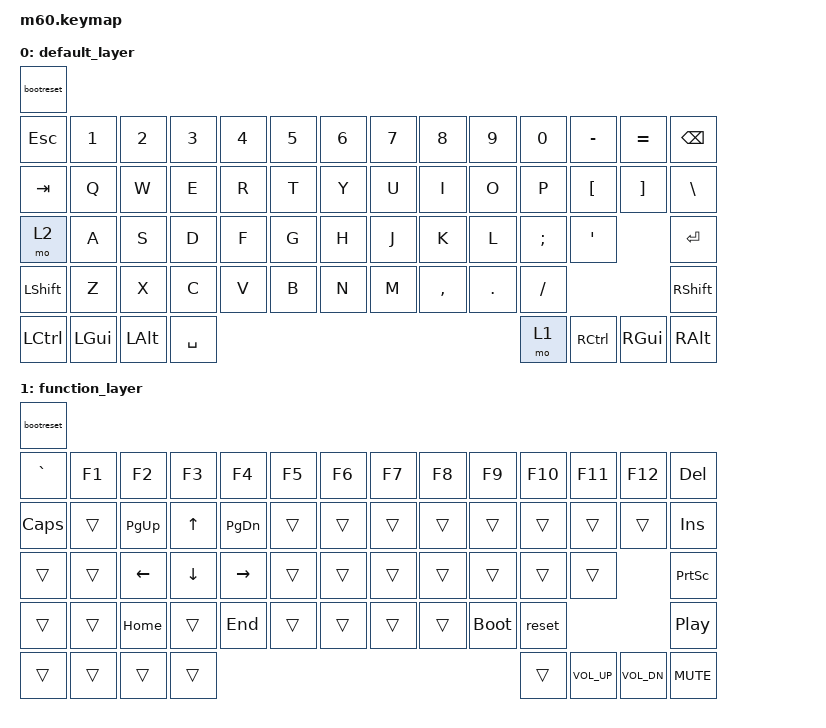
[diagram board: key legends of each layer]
/*
 * Copyright (c) 2020 The ZMK Contributors
 *
 * SPDX-License-Identifier: MIT
 */

#include <behaviors.dtsi>
#include <dt-bindings/zmk/keys.h>
#include <dt-bindings/zmk/bt.h>

/ {
	behaviors {
		bootreset: hold_tap {
            compatible = "zmk,behavior-hold-tap";
            label = "BOOT_RESET";
            #binding-cells = <2>;
            tapping_term_ms = <150>;
            flavor = "tap-preferred";
            bindings = <&bootloader>, <&reset>;
        };
	};

	keymap0: keymap {
		compatible = "zmk,keymap";

		default_layer {
			bindings = <
&bootreset
&kp ESC   &kp N1   &kp N2   &kp N3 &kp N4 &kp N5 &kp N6 &kp N7 &kp N8    &kp N9  &kp N0   &kp MINUS &kp EQUAL &kp BSPC
&kp TAB   &kp Q    &kp W    &kp E  &kp R  &kp T  &kp Y  &kp U  &kp I     &kp O   &kp P    &kp LBKT  &kp RBKT  &kp BSLH
&mo 2     &kp A    &kp S    &kp D  &kp F  &kp G  &kp H  &kp J  &kp K     &kp L   &kp SEMI &kp SQT             &kp RET
&kp LSHFT &kp Z    &kp X    &kp C  &kp V  &kp B  &kp N  &kp M  &kp COMMA &kp DOT &kp FSLH                     &kp RSHFT
&kp LCTRL &kp LGUI &kp LALT &kp SPACE                                            &mo 1    &kp RCTRL &kp RGUI  &kp RALT
			>;
		};

		function_layer {
			bindings = <
&bootreset
&kp GRAVE &kp F1   &kp F2    &kp F3   &kp F4    &kp F5  &kp F6 &kp F7 &kp F8 &kp F9       &kp F10 &kp F11      &kp F12      &kp DEL
&kp CLCK  &trans   &kp PG_UP &kp UP   &kp PG_DN &trans  &trans &trans &trans &trans       &trans  &trans       &trans       &kp INSERT
&trans    &trans   &kp LEFT  &kp DOWN &kp RIGHT &trans  &trans &trans &trans &trans       &trans  &trans                    &kp PSCRN
&trans    &trans   &kp HOME  &trans   &kp END   &trans  &trans &trans &trans &bootloader  &reset                            &kp C_PLAY_PAUSE
&trans    &trans   &trans    &trans                                                       &trans  &kp C_VOL_UP &kp C_VOL_DN &kp C_MUTE
			>;
		};
	};
};
